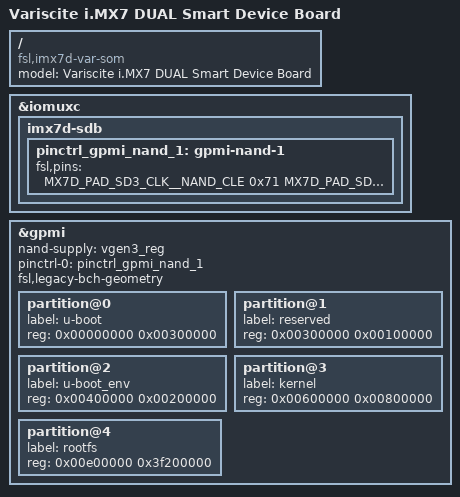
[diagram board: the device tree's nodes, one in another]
/*
 * Copyright (C) 2015 Freescale Semiconductor, Inc.
 * Copyright (C) 2016-2017 Variscite Ltd.
 *
 * This program is free software; you can redistribute it and/or modify
 * it under the terms of the GNU General Public License version 2 as
 * published by the Free Software Foundation.
 */
/dts-v1/;

#include "imx7d.dtsi"
#include "imx7d-var-som.dtsi"

/ {
	model = "Variscite i.MX7 DUAL Smart Device Board";
	compatible = "fsl,imx7d-var-som", "fsl,imx7d";
};

&iomuxc {
	imx7d-sdb {
		pinctrl_gpmi_nand_1: gpmi-nand-1 {
			fsl,pins = <
				MX7D_PAD_SD3_CLK__NAND_CLE		0x71
				MX7D_PAD_SD3_CMD__NAND_ALE		0x71
				MX7D_PAD_SAI1_MCLK__NAND_WP_B		0x71
				MX7D_PAD_SAI1_TX_BCLK__NAND_CE0_B	0x71
				MX7D_PAD_SAI1_RX_DATA__NAND_CE1_B	0x71
				MX7D_PAD_SAI1_TX_DATA__NAND_READY_B	0x74
				MX7D_PAD_SD3_STROBE__NAND_RE_B		0x71
				MX7D_PAD_SD3_RESET_B__NAND_WE_B		0x71
				MX7D_PAD_SD3_DATA0__NAND_DATA00		0x71
				MX7D_PAD_SD3_DATA1__NAND_DATA01		0x71
				MX7D_PAD_SD3_DATA2__NAND_DATA02		0x71
				MX7D_PAD_SD3_DATA3__NAND_DATA03		0x71
				MX7D_PAD_SD3_DATA4__NAND_DATA04		0x71
				MX7D_PAD_SD3_DATA5__NAND_DATA05		0x71
				MX7D_PAD_SD3_DATA6__NAND_DATA06		0x71
				MX7D_PAD_SD3_DATA7__NAND_DATA07		0x71
			>;
		};
	};
};

&gpmi {
	nand-supply = <&vgen3_reg>;
	pinctrl-names = "default";
	pinctrl-0 = <&pinctrl_gpmi_nand_1>;
	fsl,legacy-bch-geometry;
	status = "okay";

	/* a 3 MiB partition */
	partition@0 {
		label = "u-boot";
		reg = <0x00000000 0x00300000>;
	};

	/* a 1 MiB partition */
	partition@1 {
		label = "reserved";
		reg = <0x00300000 0x00100000>;
	};

	/* a 2 MiB partition */
	partition@2 {
		label = "u-boot_env";
		reg = <0x00400000 0x00200000>;
	};

	/* an 8 MiB partition */
	partition@3 {
		label = "kernel";
		reg = <0x00600000 0x00800000>;
	};

	/* a 1010 MiB partition */
	partition@4 {
		label = "rootfs";
		reg = <0x00e00000 0x3f200000>;
	};
};
